# MIMXRT1042 register map
Vendor: nxp.com; File version: 1.0
CPU: CM7 r0p1, little endian, MPU, FPU, VTOR, 4 interrupt priority bits
Registers are 32-bit, read-write, reset 0x0 unless marked. A register's access mark holds for its fields unless they carry their own. Offsets are from the block's base; [hi:lo] are bit positions; lines under a group give offsets from that group; {n}, {i} and the like mark numbered series; 'fields as' and 'values as' point back to an identical list.

## DMA0 — DMA
Base 0x400E8000
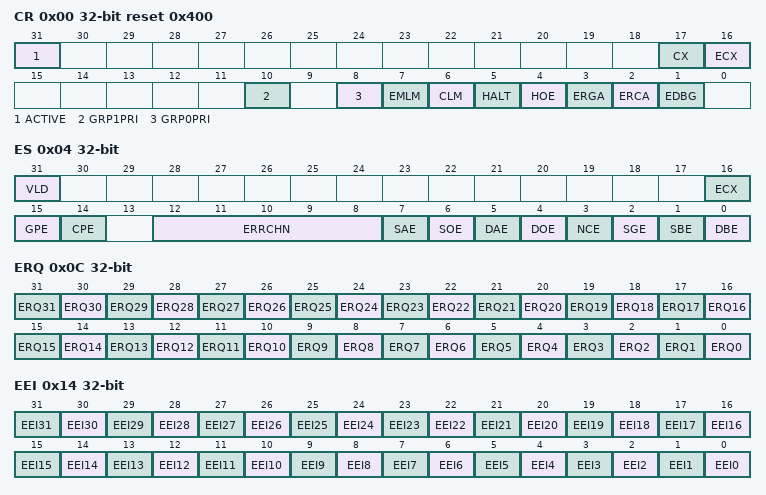
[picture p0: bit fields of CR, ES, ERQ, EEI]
0x00 CR reset 0x400 — Control
  [31] ACTIVE ro — eDMA Active Status
    0=IDLE (eDMA is idle); 1=ACTIVE (eDMA is executing a channel)
  [17] CX — Cancel Transfer
    0=NORMAL_OPS (Normal operation); 1=CANCEL (Cancel the remaining data transfer)
  [16] ECX — Error Cancel Transfer
    values as CX
  [10] GRP1PRI — Channel Group 1 Priority
  [8] GRP0PRI — Channel Group 0 Priority
  [7] EMLM — Enable Minor Loop Mapping
    0=DISABLED; 1=ENABLED
  [6] CLM — Continuous Link Mode
    0=CLM_OFF (Continuous link mode is off); 1=CLM_ON (Continuous link mode is on)
  [5] HALT — Halt eDMA Operations
    0=NORMAL_OPS (Normal operation); 1=HALT_DMA (eDMA operations halted)
  [4] HOE — Halt On Error
    0=NORMAL_OPS (Normal operation); 1=HALT_ON_ERROR (Error causes HALT field to be automatically set to 1)
  [3] ERGA — Enable Round Robin Group Arbitration
    0=DISABLED (Fixed priority arbitration); 1=ENABLED (Round robin arbitration)
  [2] ERCA — Enable Round Robin Channel Arbitration
    0=DISABLED (Fixed priority arbitration within each group); 1=ENABLED (Round robin arbitration within each group)
  [1] EDBG — Enable Debug
    0=DISABLED (When the chip is in Debug mode, the eDMA continues to operate.); 1=ENABLED (When the chip is in debug mode, the DMA stalls the start of a new channel. Executing channels are allowed to complete.)
0x04 ES ro — Error Status
  [31] VLD — Logical OR of all ERR status fields
    0=NO_ERROR (No ERR fields are 1); 1=ERROR (At least one ERR field has a value of 1, indicating a valid error exists that has not been cleared)
  [16] ECX — Transfer Canceled
    0=NO_CANCELS (No canceled transfers); 1=CANCELED (The most-recently recorded entry was a canceled transfer initiated by the error cancel transfer field)
  [15] GPE — Group Priority Error
    0=NO_ERROR (No group priority error.); 1=ERROR (The most-recently recorded error was a configuration error among the group priorities. All group priorities are not unique.)
  [14] CPE — Channel Priority Error
    0=NO_ERROR (No channel priority error.); 1=ERROR (The most-recently recorded error was a configuration error in the channel priorities within a group. Channel priorities within a group are not unique.)
  [12:8] ERRCHN — Error Channel Number or Canceled Channel Number
  [7] SAE — Source Address Error
    0=NO_ERROR (No source address configuration error.); 1=ERROR (The most-recently recorded error was a configuration error detected in the TCDn_SADDR field. TCDn_SADDR is inconsistent with TCDn_ATTR[SSIZE].)
  [6] SOE — Source Offset Error
    0=NO_ERROR (No source offset configuration error.); 1=ERROR (The most-recently recorded error was a configuration error detected in the TCDn_SOFF field. TCDn_SOFF is inconsistent with TCDn_ATTR[SSIZE].)
  [5] DAE — Destination Address Error
    0=NO_ERROR (No destination address configuration error.); 1=ERROR (The most-recently recorded error was a configuration error detected in the TCDn_DADDR field. TCDn_DADDR is inconsistent with TCDn_ATTR[DSIZE].)
  [4] DOE — Destination Offset Error
    0=NO_ERROR (No destination offset configuration error.); 1=ERROR (The most-recently recorded error was a configuration error detected in the TCDn_DOFF field. TCDn_DOFF is inconsistent with TCDn_ATTR[DSIZE].)
  [3] NCE — NBYTES/CITER Configuration Error
    0=NO_ERROR (No NBYTES/CITER configuration error.); 1=ERROR (The most-recently recorded error was a configuration error detected in the TCDn_NBYTES or TCDn_CITER fields. TCDn_NBYTES is not a multiple of TCDn_ATTR[SSIZE] and TCDn_ATTR[DSIZE], or TCDn_CITER[CITER] = 0, or TCDn_CITER[ELINK] is not equal to TCDn_BITER[ELINK].)
  [2] SGE — Scatter/Gather Configuration Error
    0=NO_ERROR (No scatter/gather configuration error.); 1=ERROR (The most-recently recorded error was a configuration error detected in the TCDn_DLASTSGA field.)
  [1] SBE — Source Bus Error
    0=NO_ERROR (No source bus error.); 1=ERROR (The most-recently recorded error was a bus error on a source read.)
  [0] DBE — Destination Bus Error
    0=NO_ERROR (No destination bus error.); 1=ERROR (The most-recently recorded error was a bus error on a destination write.)
0x0C ERQ — Enable Request
  [n] ERQ{n} (n=0..31) — Enable DMA Request {n}
    0=DISABLE (The DMA request signal for channel {n} is disabled); 1=ENABLE (The DMA request signal for channel {n} is enabled)
0x14 EEI — Enable Error Interrupt
  [n] EEI{n} (n=0..31) — Enable Error Interrupt {n}
    0=NO_INTERRUPT (An error on channel {n} does not generate an error interrupt); 1=INTERRUPT (An error on channel {n} generates an error interrupt request)
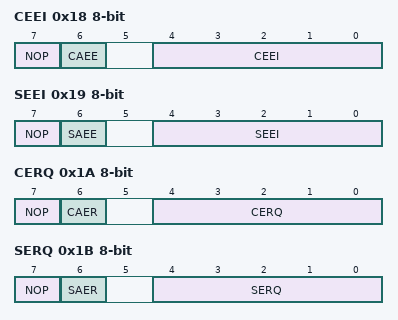
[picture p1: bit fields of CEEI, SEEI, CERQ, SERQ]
0x18 CEEI 8-bit — Clear Enable Error Interrupt
  [7] NOP — No Op Enable
    0=NORMAL_OPS (Normal operation); 1=NO_OPS (No operation, ignore the other fields in this register)
  [6] CAEE — Clear All Enable Error Interrupts
    0=CLEAR_EEI (Write 0 only to the EEI field specified in the CEEI field); 1=CLEAR_ALL (Write 0 to all fields in EEI)
  [4:0] CEEI — Clear Enable Error Interrupt
0x19 SEEI 8-bit — Set Enable Error Interrupt
  [7] NOP — No Op Enable
    values as CEEI.NOP
  [6] SAEE — Set All Enable Error Interrupts
    0=SET_EEI (Write 1 only to the EEI field specified in the SEEI field); 1=SET_ALL (Writes 1 to all fields in EEI)
  [4:0] SEEI — Set Enable Error Interrupt
0x1A CERQ 8-bit — Clear Enable Request
  [7] NOP — No Op Enable
    values as CEEI.NOP
  [6] CAER — Clear All Enable Requests
    0=CLEAR_ERQ (Write 0 to only the ERQ field specified in the CERQ field); 1=CLEAR_ALL (Write 0 to all fields in ERQ)
  [4:0] CERQ — Clear Enable Request
0x1B SERQ 8-bit — Set Enable Request
  [7] NOP — No Op Enable
    values as CEEI.NOP
  [6] SAER — Set All Enable Requests
    0=SET_ERQ (Write 1 to only the ERQ field specified in the SERQ field); 1=SET_ALL (Write 1 to all fields in ERQ)
  [4:0] SERQ — Set Enable Request
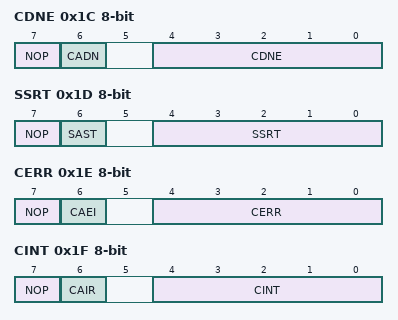
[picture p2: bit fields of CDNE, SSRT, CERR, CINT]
0x1C CDNE 8-bit — Clear DONE Status Bit
  [7] NOP — No Op Enable
    0=NORMAL_OPS (Normal operation); 1=NO_OPS (No operation; all other fields in this register are ignored.)
  [6] CADN — Clears All DONE fields
    0=CLEAR_DONE (Writes 0 to only the TCDn_CSR[DONE] field specified in the CDNE field); 1=CLEAR_ALL (Writes 0 to all bits in TCDn_CSR[DONE])
  [4:0] CDNE — Clear DONE field
0x1D SSRT 8-bit — Set START Bit
  [7] NOP — No Op Enable
    values as CDNE.NOP
  [6] SAST — Set All START fields (activates all channels)
    0=SET_START (Write 1 to only the TCDn_CSR[START] field specified in the SSRT field); 1=SET_ALL (Write 1 to all bits in TCDn_CSR[START])
  [4:0] SSRT — Set START field
0x1E CERR 8-bit — Clear Error
  [7] NOP — No Op Enable
    values as CDNE.NOP
  [6] CAEI — Clear All Error Indicators
    0=CLEAR_ERR (Write 0 to only the ERR field specified in the CERR field); 1=CLEAR_ALL (Write 0 to all fields in ERR)
  [4:0] CERR — Clear Error Indicator
0x1F CINT 8-bit — Clear Interrupt Request
  [7] NOP — No Op Enable
    values as CDNE.NOP
  [6] CAIR — Clear All Interrupt Requests
    0=CLEAR_INT (Clear only the INT field specified in the CINT field); 1=CLEAR_ALL (Clear all bits in INT)
  [4:0] CINT — Clear Interrupt Request
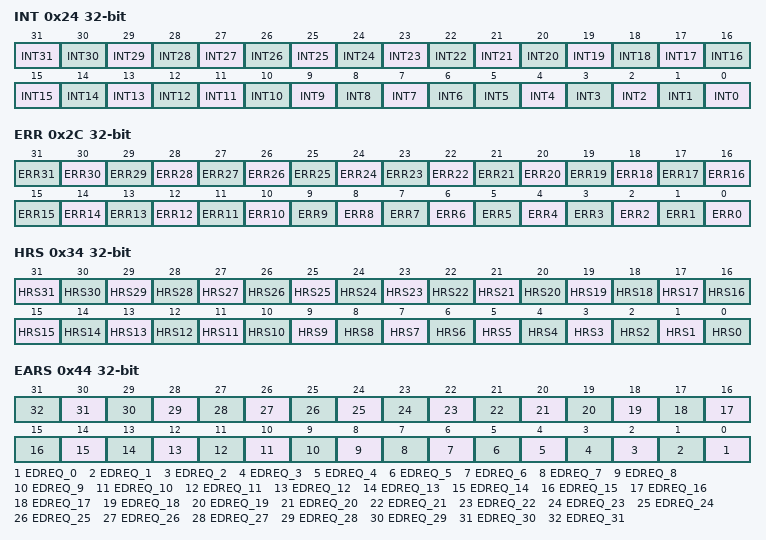
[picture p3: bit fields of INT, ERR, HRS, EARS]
0x24 INT write-1-clears — Interrupt Request
  [n] INT{n} write-1-clears (n=7..31) — Interrupt Request {n}
    0=NOT_ACTIVE (The interrupt request for channel {n} is cleared); 1=ACTIVE (The interrupt request for channel {n} is active)
  [6] INT6 write-1-clears — Interrupt Request 6
    0=NOT_ACTIVE (The interrupt request for channel 6 is cleared); 1=CTIVE (The interrupt request for channel 6 is active)
  [n] INT{n} write-1-clears (n=0..5) — Interrupt Request {n}
    values as INT7
0x2C ERR write-1-clears — Error
  [all] fields
    0=NO_ERR (No error in this channel has occurred); 1=ERR (An error in this channel has occurred)
  [n] ERR{n} write-1-clears (n=0..31) — Error In Channel {n}
0x34 HRS ro — Hardware Request Status
  [31] HRS31 — Hardware Request Status Channel 31
    0=NO_HWRQST (A hardware service request for channel 31 is not present); 1=HWRQST (A hardware service request for channel 31 is present)
  [30] HRS30 — Hardware Request Status Channel 30
    0=NO_HWRQST (A hardware service request for channel 30 is not present); 1=HWRQST (A hardware service request for channel 30 is present)
  [29] HRS29 — Hardware Request Status Channel 29
    0=NO_HWRQST (A hardware service request for channel 29 is not preset); 1=HWRQST (A hardware service request for channel 29 is present)
  [n] HRS{n} (n=0..28) — Hardware Request Status Channel {n}
    0=NO_HWRQST (A hardware service request for channel {n} is not present); 1=HWRQST (A hardware service request for channel {n} is present)
0x44 EARS — Enable Asynchronous Request in Stop
  [n] EDREQ_{n} (n=0..31) — Enable asynchronous DMA request in stop mode for channel {n}.
    0=DISABLE (Disable asynchronous DMA request for channel {n}); 1=ENABLE (Enable asynchronous DMA request for channel {n})
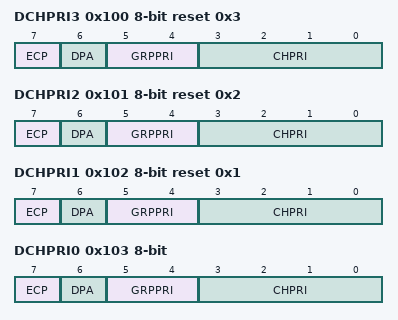
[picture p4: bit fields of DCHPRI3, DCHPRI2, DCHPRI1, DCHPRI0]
0x100 DCHPRI3 8-bit reset 0x3 — Channel Priority
  [7] ECP — Enable Channel Preemption. This field resets to 0.
    0=DISABLED (Channel n cannot be suspended by a higher priority channel's service request); 1=ENABLED (Channel n can be temporarily suspended by the service request of a higher priority channel)
  [6] DPA — Disable Preempt Ability. This field resets to 0.
    0=ENABLED (Channel n can suspend a lower priority channel); 1=DISABLED (Channel n cannot suspend any channel, regardless of channel priority)
  [5:4] GRPPRI ro — Channel n Current Group Priority
  [3:0] CHPRI — Channel n Arbitration Priority
0x101 DCHPRI2 8-bit reset 0x2 — Channel Priority
  fields as DCHPRI3
0x102 DCHPRI1 8-bit reset 0x1 — Channel Priority
  fields as DCHPRI3
0x103 DCHPRI0 8-bit — Channel Priority
  fields as DCHPRI3
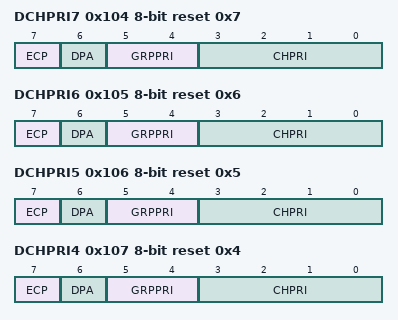
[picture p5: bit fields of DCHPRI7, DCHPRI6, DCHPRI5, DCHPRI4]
0x104 DCHPRI7 8-bit reset 0x7 — Channel Priority
  fields as DCHPRI3
0x105 DCHPRI6 8-bit reset 0x6 — Channel Priority
  fields as DCHPRI3
0x106 DCHPRI5 8-bit reset 0x5 — Channel Priority
  fields as DCHPRI3
0x107 DCHPRI4 8-bit reset 0x4 — Channel Priority
  fields as DCHPRI3
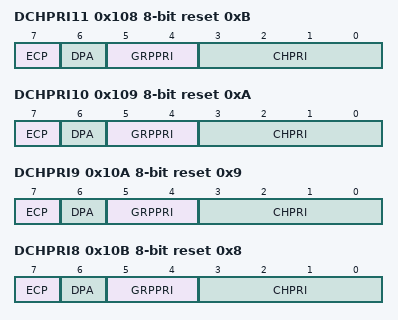
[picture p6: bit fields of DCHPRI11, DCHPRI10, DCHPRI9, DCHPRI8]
0x108 DCHPRI11 8-bit reset 0xB — Channel Priority
  fields as DCHPRI3
0x109 DCHPRI10 8-bit reset 0xA — Channel Priority
  fields as DCHPRI3
0x10A DCHPRI9 8-bit reset 0x9 — Channel Priority
  fields as DCHPRI3
0x10B DCHPRI8 8-bit reset 0x8 — Channel Priority
  fields as DCHPRI3
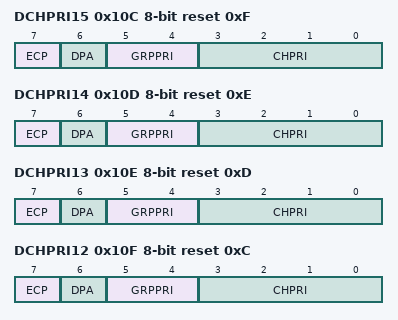
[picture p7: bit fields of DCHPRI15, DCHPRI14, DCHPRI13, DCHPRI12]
0x10C DCHPRI15 8-bit reset 0xF — Channel Priority
  fields as DCHPRI3
0x10D DCHPRI14 8-bit reset 0xE — Channel Priority
  fields as DCHPRI3
0x10E DCHPRI13 8-bit reset 0xD — Channel Priority
  fields as DCHPRI3
0x10F DCHPRI12 8-bit reset 0xC — Channel Priority
  fields as DCHPRI3
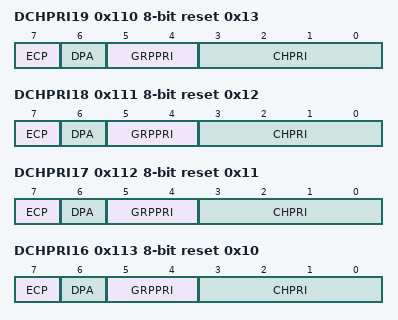
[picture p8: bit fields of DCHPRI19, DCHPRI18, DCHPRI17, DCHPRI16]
0x110 DCHPRI19 8-bit reset 0x13 — Channel Priority
  fields as DCHPRI3
0x111 DCHPRI18 8-bit reset 0x12 — Channel Priority
  fields as DCHPRI3
0x112 DCHPRI17 8-bit reset 0x11 — Channel Priority
  fields as DCHPRI3
0x113 DCHPRI16 8-bit reset 0x10 — Channel Priority
  fields as DCHPRI3
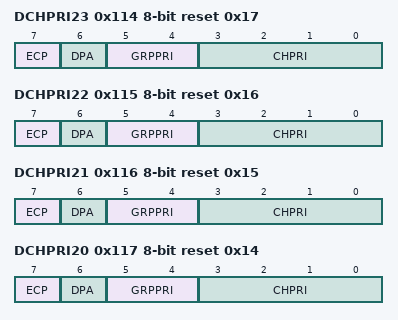
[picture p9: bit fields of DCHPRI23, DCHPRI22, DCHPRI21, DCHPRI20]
0x114 DCHPRI23 8-bit reset 0x17 — Channel Priority
  fields as DCHPRI3
0x115 DCHPRI22 8-bit reset 0x16 — Channel Priority
  fields as DCHPRI3
0x116 DCHPRI21 8-bit reset 0x15 — Channel Priority
  fields as DCHPRI3
0x117 DCHPRI20 8-bit reset 0x14 — Channel Priority
  fields as DCHPRI3
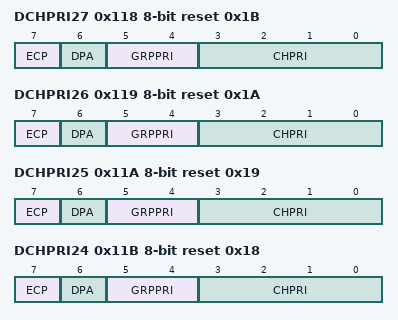
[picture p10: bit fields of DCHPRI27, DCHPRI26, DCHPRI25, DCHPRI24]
0x118 DCHPRI27 8-bit reset 0x1B — Channel Priority
  fields as DCHPRI3
0x119 DCHPRI26 8-bit reset 0x1A — Channel Priority
  fields as DCHPRI3
0x11A DCHPRI25 8-bit reset 0x19 — Channel Priority
  fields as DCHPRI3
0x11B DCHPRI24 8-bit reset 0x18 — Channel Priority
  fields as DCHPRI3
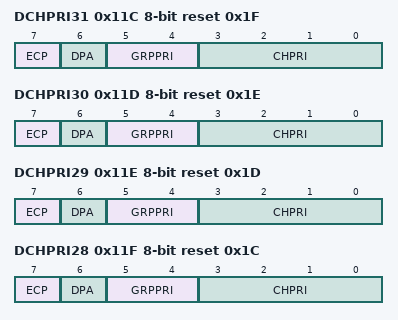
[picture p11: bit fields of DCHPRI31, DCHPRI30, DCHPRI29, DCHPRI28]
0x11C DCHPRI31 8-bit reset 0x1F — Channel Priority
  fields as DCHPRI3
0x11D DCHPRI30 8-bit reset 0x1E — Channel Priority
  fields as DCHPRI3
0x11E DCHPRI29 8-bit reset 0x1D — Channel Priority
  fields as DCHPRI3
0x11F DCHPRI28 8-bit reset 0x1C — Channel Priority
  fields as DCHPRI3
{0x1000+0x20*i} TCD{i}_SADDR reset not defined (i=0..31) — TCD Source Address
  [31:0] SADDR — Source Address
{0x1004+0x20*i} TCD{i}_SOFF 16-bit reset not defined (i=0..31) — TCD Signed Source Address Offset
  [15:0] SOFF — Source address signed offset
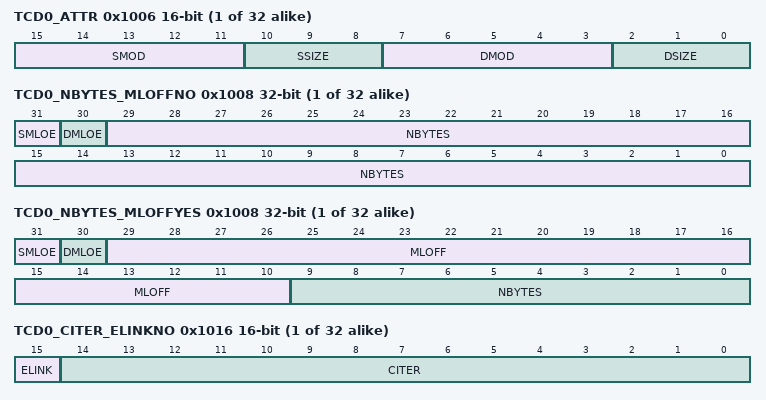
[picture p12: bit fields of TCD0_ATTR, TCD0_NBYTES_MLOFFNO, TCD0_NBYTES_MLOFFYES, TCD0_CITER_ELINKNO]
{0x1006+0x20*i} TCD{i}_ATTR 16-bit reset not defined (i=0..31) — TCD Transfer Attributes
  [15:11] SMOD — Source Address Modulo
    0=DISABLED (Source address modulo feature is disabled); {v}=ENABLED_{v} (Value defines address range used to set up circular data queue) (v=1..9)
  [10:8] SSIZE — Source data transfer size
    0=EIGHT (8-bit); 1=SIXTEEN_BIT (16-bit); 2=THIRTYTWO_BIT (32-bit); 3=SIXTYFOUR (64-bit); 5=THIRTYTWO_BYTE (32-byte burst (4 beats of 64 bits))
  [7:3] DMOD — Destination Address Modulo
  [2:0] DSIZE — Destination data transfer size
{0x1008+0x20*i} TCD{i}_NBYTES_MLNO reset not defined (TCD_NBYTES view) (i=0..31) — TCD Minor Byte Count (Minor Loop Mapping Disabled)
  [31:0] NBYTES — Minor Byte Transfer Count
{0x1008+0x20*i} TCD{i}_NBYTES_MLOFFNO reset not defined (TCD_NBYTES view) (i=0..31) — TCD Signed Minor Loop Offset (Minor Loop Mapping Enabled and Offset Disabled)
  [31] SMLOE — Source Minor Loop Offset Enable
    0=DISABLED (The minor loop offset is not applied to the SADDR); 1=ENABLED (The minor loop offset is applied to the SADDR)
  [30] DMLOE — Destination Minor Loop Offset Enable
    0=DISABLED (The minor loop offset is not applied to the DADDR); 1=ENABLED (The minor loop offset is applied to the DADDR)
  [29:0] NBYTES — Minor Byte Transfer Count
{0x1008+0x20*i} TCD{i}_NBYTES_MLOFFYES reset not defined (TCD_NBYTES view) (i=0..31) — TCD Signed Minor Loop Offset (Minor Loop Mapping and Offset Enabled)
  [31] SMLOE — Source Minor Loop Offset Enable
    values as TCD0_NBYTES_MLOFFNO.SMLOE
  [30] DMLOE — Destination Minor Loop Offset Enable
    values as TCD0_NBYTES_MLOFFNO.DMLOE
  [29:10] MLOFF — If SMLOE = 1 or DMLOE = 1, this field represents a sign-extended offset applied to the source or destination address to form the next-state value after the minor loop completes.
  [9:0] NBYTES — Minor Byte Transfer Count
{0x100C+0x20*i} TCD{i}_SLAST reset not defined (i=0..31) — TCD Last Source Address Adjustment
  [31:0] SLAST — Last Source Address Adjustment
{0x1010+0x20*i} TCD{i}_DADDR reset not defined (i=0..31) — TCD Destination Address
  [31:0] DADDR — Destination Address
{0x1014+0x20*i} TCD{i}_DOFF 16-bit reset not defined (i=0..31) — TCD Signed Destination Address Offset
  [15:0] DOFF — Destination Address Signed Offset
{0x1016+0x20*i} TCD{i}_CITER_ELINKNO 16-bit reset not defined (TCD_CITER_ELINK view) (i=0..31) — TCD Current Minor Loop Link, Major Loop Count (Channel Linking Disabled)
  [15] ELINK — Enable channel-to-channel linking on minor-loop complete
    0=DISABLED (Channel-to-channel linking is disabled); 1=ENABLED (Channel-to-channel linking is enabled)
  [14:0] CITER — Current Major Iteration Count
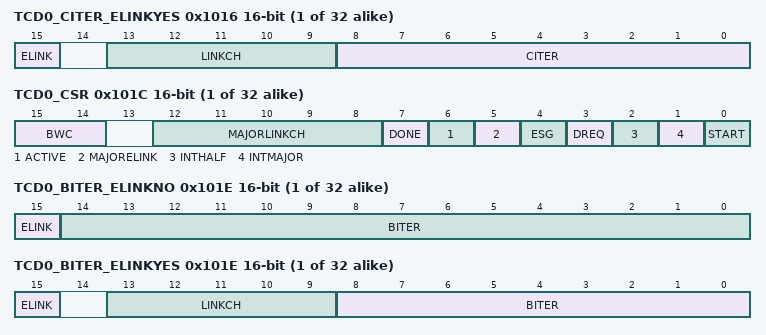
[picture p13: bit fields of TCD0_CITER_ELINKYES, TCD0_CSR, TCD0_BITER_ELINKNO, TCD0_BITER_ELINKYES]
{0x1016+0x20*i} TCD{i}_CITER_ELINKYES 16-bit reset not defined (TCD_CITER_ELINK view) (i=0..31) — TCD Current Minor Loop Link, Major Loop Count (Channel Linking Enabled)
  [15] ELINK — Enable channel-to-channel linking on minor-loop complete
    values as TCD0_CITER_ELINKNO.ELINK
  [13:9] LINKCH — Minor Loop Link Channel Number
  [8:0] CITER — Current Major Iteration Count
{0x1018+0x20*i} TCD{i}_DLASTSGA reset not defined (i=0..31) — TCD Last Destination Address Adjustment/Scatter Gather Address
  [31:0] DLASTSGA — Destination last address adjustment, or next memory address TCD for channel (scatter/gather)
{0x101C+0x20*i} TCD{i}_CSR 16-bit reset not defined (i=0..31) — TCD Control and Status
  [15:14] BWC — Bandwidth Control
    0=DISABLED (No eDMA engine stalls); 2=STALL4 (eDMA engine stalls for 4 cycles after each R/W); 3=STALL8 (eDMA engine stalls for 8 cycles after each R/W)
  [12:8] MAJORLINKCH — Major Loop Link Channel Number
  [7] DONE — Channel Done
  [6] ACTIVE ro — Channel Active
  [5] MAJORELINK — Enable channel-to-channel linking on major loop complete
    values as TCD0_CITER_ELINKNO.ELINK
  [4] ESG — Enable Scatter/Gather Processing
    0=NORMAL (The current channel's TCD is normal format); 1=SCATTER (The current channel's TCD specifies a scatter gather format)
  [3] DREQ — Disable Request
    0=NO_CLEAR (The channel's ERQ field is not affected); 1=CLEAR (The channel's ERQ field value changes to 0 when the major loop is complete)
  [2] INTHALF — Enable an interrupt when major counter is half complete.
    0=DISABLED (Half-point interrupt is disabled); 1=ENABLED (Half-point interrupt is enabled)
  [1] INTMAJOR — Enable an interrupt when major iteration count completes.
    0=DISABLED (End of major loop interrupt is disabled); 1=ENABLED (End of major loop interrupt is enabled)
  [0] START — Channel Start
    0=NO_START (Channel is not explicitly started); 1=START (Channel is explicitly started via a software initiated service request)
{0x101E+0x20*i} TCD{i}_BITER_ELINKNO 16-bit reset not defined (TCD_BITER_ELINK view) (i=0..31) — TCD Beginning Minor Loop Link, Major Loop Count (Channel Linking Disabled)
  [15] ELINK — Enables channel-to-channel linking on minor loop complete
    values as TCD0_CITER_ELINKNO.ELINK
  [14:0] BITER — Starting Major Iteration Count
{0x101E+0x20*i} TCD{i}_BITER_ELINKYES 16-bit reset not defined (TCD_BITER_ELINK view) (i=0..31) — TCD Beginning Minor Loop Link, Major Loop Count (Channel Linking Enabled)
  [15] ELINK — Enables channel-to-channel linking on minor loop complete
    values as TCD0_CITER_ELINKNO.ELINK
  [13:9] LINKCH — Link Channel Number
  [8:0] BITER — Starting major iteration count
